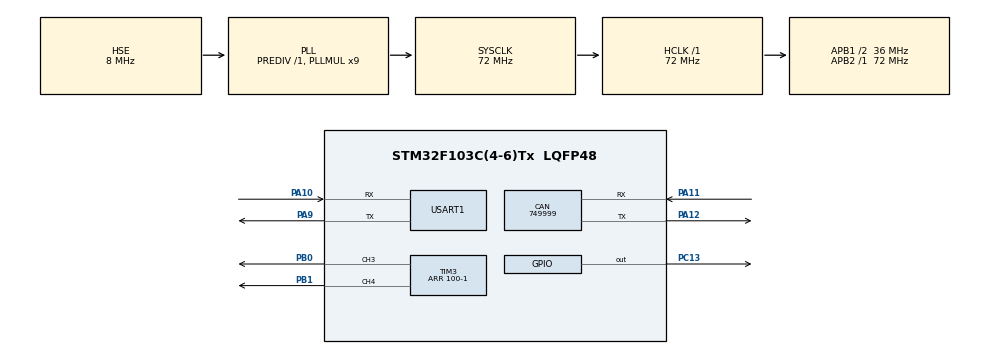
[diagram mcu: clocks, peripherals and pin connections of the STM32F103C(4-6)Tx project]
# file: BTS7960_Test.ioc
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CAN.CalculateBaudRate=749999
CAN.CalculateTimeBit=1333
CAN.CalculateTimeQuantum=444.44444444444446
Dma.Request0=TIM3_CH3
Dma.Request1=TIM3_CH4/UP
Dma.TIM3_CH3.0.Direction=DMA_MEMORY_TO_PERIPH
Dma.TIM3_CH3.0.Instance=DMA1_Channel2
Dma.TIM3_CH3.0.MemDataAlignment=DMA_MDATAALIGN_HALFWORD
Dma.TIM3_CH3.0.MemInc=DMA_MINC_ENABLE
Dma.TIM3_CH3.0.Mode=DMA_NORMAL
Dma.TIM3_CH3.0.PeriphDataAlignment=DMA_PDATAALIGN_HALFWORD
Dma.TIM3_CH3.0.PeriphInc=DMA_PINC_DISABLE
Dma.TIM3_CH3.0.Priority=DMA_PRIORITY_LOW
Dma.TIM3_CH4/UP.1.Direction=DMA_MEMORY_TO_PERIPH
Dma.TIM3_CH4/UP.1.Instance=DMA1_Channel3
Dma.TIM3_CH4/UP.1.MemDataAlignment=DMA_MDATAALIGN_HALFWORD
Dma.TIM3_CH4/UP.1.MemInc=DMA_MINC_ENABLE
Dma.TIM3_CH4/UP.1.Mode=DMA_NORMAL
Dma.TIM3_CH4/UP.1.PeriphDataAlignment=DMA_PDATAALIGN_HALFWORD
Dma.TIM3_CH4/UP.1.PeriphInc=DMA_PINC_DISABLE
Dma.TIM3_CH4/UP.1.Priority=DMA_PRIORITY_LOW
Mcu.Family=STM32F1
Mcu.Name=STM32F103C(4-6)Tx
Mcu.Package=LQFP48
NVIC.DMA1_Channel2_IRQn=true\:0\:0\:false\:false\:true\:false\:true\:true
NVIC.DMA1_Channel3_IRQn=true\:0\:0\:false\:false\:true\:false\:true\:true
NVIC.PriorityGroup=NVIC_PRIORITYGROUP_4
PA10.Mode=Asynchronous
PA10.Signal=USART1_RX
PA11.Mode=CAN_Activate
PA11.Signal=CAN_RX
PA12.Mode=CAN_Activate
PA12.Signal=CAN_TX
PA9.Mode=Asynchronous
PA9.Signal=USART1_TX
PB0.Signal=S_TIM3_CH3
PB1.Signal=S_TIM3_CH4
PC13-TAMPER-RTC.Signal=GPIO_Output
PD0-OSC_IN.Mode=HSE-External-Oscillator
PD0-OSC_IN.Signal=RCC_OSC_IN
PD1-OSC_OUT.Mode=HSE-External-Oscillator
PD1-OSC_OUT.Signal=RCC_OSC_OUT
ProjectManager.HeapSize=0x200
ProjectManager.StackSize=0x400
ProjectManager.TargetToolchain=STM32CubeIDE
RCC.AHBFreq_Value=72000000
RCC.APB1CLKDivider=RCC_HCLK_DIV2
RCC.APB1Freq_Value=36000000
RCC.APB1TimFreq_Value=72000000
RCC.APB2Freq_Value=72000000
RCC.APB2TimFreq_Value=72000000
RCC.HCLKFreq_Value=72000000
RCC.PLLMUL=RCC_PLL_MUL9
RCC.PLLSourceVirtual=RCC_PLLSOURCE_HSE
RCC.SYSCLKFreq_VALUE=72000000
RCC.SYSCLKSource=RCC_SYSCLKSOURCE_PLLCLK
RCC.USBFreq_Value=72000000
SH.S_TIM3_CH3.0=TIM3_CH3,PWM Generation3 CH3
SH.S_TIM3_CH4.0=TIM3_CH4,PWM Generation4 CH4
TIM3.Channel-PWM\ Generation3\ CH3=TIM_CHANNEL_3
TIM3.Channel-PWM\ Generation4\ CH4=TIM_CHANNEL_4
TIM3.Period=100-1
USART1.VirtualMode=VM_ASYNC
VP_SYS_VS_ND.Mode=No_Debug
board=custom

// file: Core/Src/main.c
/* USER CODE BEGIN Header */
/**
  ******************************************************************************
  * @file           : main.c
  * @brief          : Main program body
  ******************************************************************************
  * @attention
  *
  * Copyright (c) 2024 STMicroelectronics.
  * All rights reserved.
  *
  * This software is licensed under terms that can be found in the LICENSE file
  * in the root directory of this software component.
  * If no LICENSE file comes with this software, it is provided AS-IS.
  *
  ******************************************************************************
  */
/* USER CODE END Header */
#include "main.h"
#include <stdlib.h>

CAN_HandleTypeDef hcan;

TIM_HandleTypeDef htim3;
DMA_HandleTypeDef hdma_tim3_ch3;
DMA_HandleTypeDef hdma_tim3_ch4_up;

UART_HandleTypeDef huart1;

void SystemClock_Config(void);
static void MX_GPIO_Init(void);
static void MX_DMA_Init(void);
static void MX_CAN_Init(void);
static void MX_TIM3_Init(void);
static void MX_USART1_UART_Init(void);

/* USER CODE BEGIN 0 */
uint32_t L_PWM, R_PWM;
const uint32_t L_PWM_RESET = 0, R_PWM_RESET = 0;

void RotateMotor(int32_t value){
	R_PWM = value > 0 ? value : 0;
	L_PWM = value < 0 ? -value : 0;
	HAL_TIM_PWM_Start_DMA(&htim3, TIM_CHANNEL_3, &R_PWM_RESET, 1);
	HAL_TIM_PWM_Start_DMA(&htim3, TIM_CHANNEL_4, &L_PWM_RESET, 1);
	HAL_TIM_PWM_Start_DMA(&htim3, TIM_CHANNEL_3, &R_PWM, 1);
	HAL_TIM_PWM_Start_DMA(&htim3, TIM_CHANNEL_4, &L_PWM, 1);
}

/* USER CODE END 0 */

int main(void)
{

  /* MCU Configuration--------------------------------------------------------*/

  /* Reset of all peripherals, Initializes the Flash interface and the Systick. */
  HAL_Init();

  /* Configure the system clock */
  SystemClock_Config();

  /* Initialize all configured peripherals */
  MX_GPIO_Init();
  MX_DMA_Init();
  MX_CAN_Init();
  MX_TIM3_Init();
  MX_USART1_UART_Init();

  /* Infinite loop */
  while (1)
  {
	  for (int i = 0; i < 5; i++) {
		  RotateMotor(i*20);
		  HAL_GPIO_WritePin(GPIOC, GPIO_PIN_13, RESET);
		  HAL_Delay(200);
	  }
	  for (int i = 4; i >= 0; i--) {
		  RotateMotor(-i*20);
		  HAL_GPIO_WritePin(GPIOC, GPIO_PIN_13, SET);
		  HAL_Delay(200);
	  }
  }
}

void SystemClock_Config(void)
{
  RCC_OscInitTypeDef RCC_OscInitStruct = {0};
  RCC_ClkInitTypeDef RCC_ClkInitStruct = {0};

  /** Initializes the RCC Oscillators according to the specified parameters
  * in the RCC_OscInitTypeDef structure.
  */
  RCC_OscInitStruct.OscillatorType = RCC_OSCILLATORTYPE_HSE;
  RCC_OscInitStruct.HSEState = RCC_HSE_ON;
  RCC_OscInitStruct.HSEPredivValue = RCC_HSE_PREDIV_DIV1;
  RCC_OscInitStruct.HSIState = RCC_HSI_ON;
  RCC_OscInitStruct.PLL.PLLState = RCC_PLL_ON;
  RCC_OscInitStruct.PLL.PLLSource = RCC_PLLSOURCE_HSE;
  RCC_OscInitStruct.PLL.PLLMUL = RCC_PLL_MUL9;
  if (HAL_RCC_OscConfig(&RCC_OscInitStruct) != HAL_OK)
  {
    Error_Handler();
  }

  /** Initializes the CPU, AHB and APB buses clocks
  */
  RCC_ClkInitStruct.ClockType = RCC_CLOCKTYPE_HCLK|RCC_CLOCKTYPE_SYSCLK
                              |RCC_CLOCKTYPE_PCLK1|RCC_CLOCKTYPE_PCLK2;
  RCC_ClkInitStruct.SYSCLKSource = RCC_SYSCLKSOURCE_PLLCLK;
  RCC_ClkInitStruct.AHBCLKDivider = RCC_SYSCLK_DIV1;
  RCC_ClkInitStruct.APB1CLKDivider = RCC_HCLK_DIV2;
  RCC_ClkInitStruct.APB2CLKDivider = RCC_HCLK_DIV1;

  if (HAL_RCC_ClockConfig(&RCC_ClkInitStruct, FLASH_LATENCY_2) != HAL_OK)
  {
    Error_Handler();
  }
}

static void MX_CAN_Init(void)
{

  hcan.Instance = CAN1;
  hcan.Init.Prescaler = 16;
  hcan.Init.Mode = CAN_MODE_NORMAL;
  hcan.Init.SyncJumpWidth = CAN_SJW_1TQ;
  hcan.Init.TimeSeg1 = CAN_BS1_1TQ;
  hcan.Init.TimeSeg2 = CAN_BS2_1TQ;
  hcan.Init.TimeTriggeredMode = DISABLE;
  hcan.Init.AutoBusOff = DISABLE;
  hcan.Init.AutoWakeUp = DISABLE;
  hcan.Init.AutoRetransmission = DISABLE;
  hcan.Init.ReceiveFifoLocked = DISABLE;
  hcan.Init.TransmitFifoPriority = DISABLE;
  if (HAL_CAN_Init(&hcan) != HAL_OK)
  {
    Error_Handler();
  }

}

static void MX_TIM3_Init(void)
{

  TIM_MasterConfigTypeDef sMasterConfig = {0};
  TIM_OC_InitTypeDef sConfigOC = {0};

  htim3.Instance = TIM3;
  htim3.Init.Prescaler = 0;
  htim3.Init.CounterMode = TIM_COUNTERMODE_UP;
  htim3.Init.Period = 100-1;
  htim3.Init.ClockDivision = TIM_CLOCKDIVISION_DIV1;
  htim3.Init.AutoReloadPreload = TIM_AUTORELOAD_PRELOAD_DISABLE;
  if (HAL_TIM_PWM_Init(&htim3) != HAL_OK)
  {
    Error_Handler();
  }
  sMasterConfig.MasterOutputTrigger = TIM_TRGO_RESET;
  sMasterConfig.MasterSlaveMode = TIM_MASTERSLAVEMODE_DISABLE;
  if (HAL_TIMEx_MasterConfigSynchronization(&htim3, &sMasterConfig) != HAL_OK)
  {
    Error_Handler();
  }
  sConfigOC.OCMode = TIM_OCMODE_PWM1;
  sConfigOC.Pulse = 0;
  sConfigOC.OCPolarity = TIM_OCPOLARITY_HIGH;
  sConfigOC.OCFastMode = TIM_OCFAST_DISABLE;
  if (HAL_TIM_PWM_ConfigChannel(&htim3, &sConfigOC, TIM_CHANNEL_3) != HAL_OK)
  {
    Error_Handler();
  }
  if (HAL_TIM_PWM_ConfigChannel(&htim3, &sConfigOC, TIM_CHANNEL_4) != HAL_OK)
  {
    Error_Handler();
  }
  HAL_TIM_MspPostInit(&htim3);

}

static void MX_USART1_UART_Init(void)
{

  huart1.Instance = USART1;
  huart1.Init.BaudRate = 115200;
  huart1.Init.WordLength = UART_WORDLENGTH_8B;
  huart1.Init.StopBits = UART_STOPBITS_1;
  huart1.Init.Parity = UART_PARITY_NONE;
  huart1.Init.Mode = UART_MODE_TX_RX;
  huart1.Init.HwFlowCtl = UART_HWCONTROL_NONE;
  huart1.Init.OverSampling = UART_OVERSAMPLING_16;
  if (HAL_UART_Init(&huart1) != HAL_OK)
  {
    Error_Handler();
  }

}

static void MX_DMA_Init(void)
{

  /* DMA controller clock enable */
  __HAL_RCC_DMA1_CLK_ENABLE();

  /* DMA interrupt init */
  /* DMA1_Channel2_IRQn interrupt configuration */
  HAL_NVIC_SetPriority(DMA1_Channel2_IRQn, 0, 0);
  HAL_NVIC_EnableIRQ(DMA1_Channel2_IRQn);
  /* DMA1_Channel3_IRQn interrupt configuration */
  HAL_NVIC_SetPriority(DMA1_Channel3_IRQn, 0, 0);
  HAL_NVIC_EnableIRQ(DMA1_Channel3_IRQn);

}

static void MX_GPIO_Init(void)
{
  GPIO_InitTypeDef GPIO_InitStruct = {0};

  /* GPIO Ports Clock Enable */
  __HAL_RCC_GPIOC_CLK_ENABLE();
  __HAL_RCC_GPIOD_CLK_ENABLE();
  __HAL_RCC_GPIOB_CLK_ENABLE();
  __HAL_RCC_GPIOA_CLK_ENABLE();

  /*Configure GPIO pin Output Level */
  HAL_GPIO_WritePin(GPIOC, GPIO_PIN_13, GPIO_PIN_RESET);

  /*Configure GPIO pin : PC13 */
  GPIO_InitStruct.Pin = GPIO_PIN_13;
  GPIO_InitStruct.Mode = GPIO_MODE_OUTPUT_PP;
  GPIO_InitStruct.Pull = GPIO_NOPULL;
  GPIO_InitStruct.Speed = GPIO_SPEED_FREQ_LOW;
  HAL_GPIO_Init(GPIOC, &GPIO_InitStruct);

}

void Error_Handler(void)
{
  __disable_irq();
  while (1)
  {
  }
}
